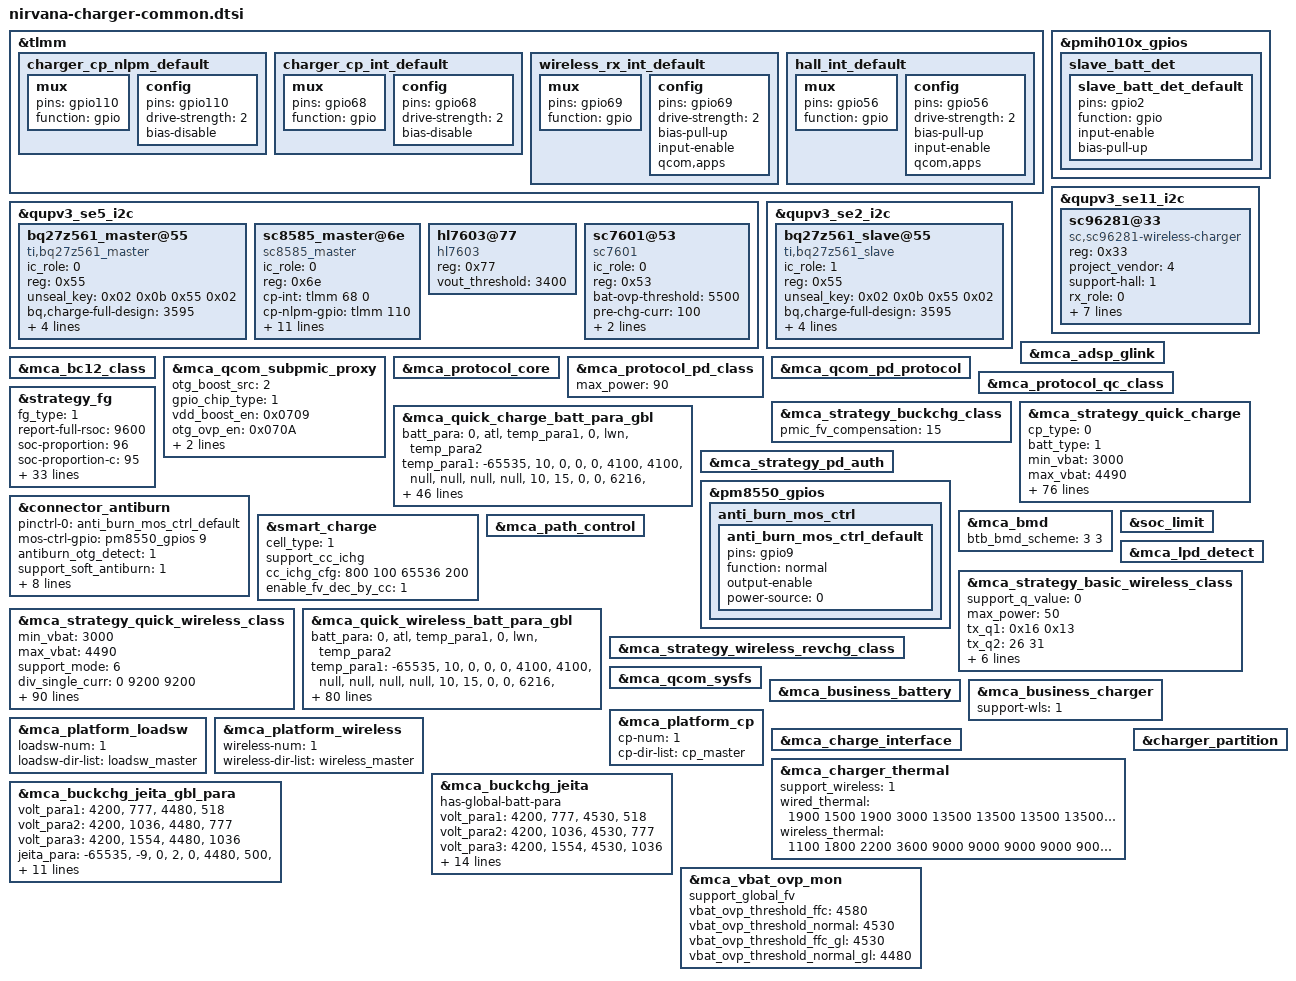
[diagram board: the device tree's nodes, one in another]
#include "mca.dtsi"

&tlmm {
	charger_cp_nlpm_default: charger_cp_nlpm_default {
		mux {
			pins = "gpio110";
			function = "gpio";
		};
		config {
			pins = "gpio110";
			drive-strength = <2>;   /* 2 mA */
			bias-disable;
		};
	};

	charger_cp_int_default: charger_cp_int_default {
		mux {
			pins = "gpio68";
			function = "gpio";
		};
		config {
			pins = "gpio68";
			drive-strength = <2>;   /* 2 mA */
			bias-disable;
		};
	};

	wireless_rx_int_default: wireless_rx_int_default {
		mux {
			pins = "gpio69";
			function = "gpio";
		};

		config {
			pins = "gpio69";
			drive-strength = <2>;
			bias-pull-up;
			input-enable;
			qcom,apps;
		};
	};

	hall_int_default: hall_int_default {
		mux {
			pins = "gpio56";
			function = "gpio";
		};

		config {
			pins = "gpio56";
			drive-strength = <2>;
			bias-pull-up;
			input-enable;
			qcom,apps;
		};
	};
};

&pmih010x_gpios {
	slave_batt_det {
		slave_batt_det_default: slave_batt_det_default {
			pins = "gpio2";
			function = "gpio";
			input-enable;
			bias-pull-up;
		};
	};
};


&qupv3_se5_i2c {
	status = "ok";
	#address-cells = <1>;
	#size-cells = <0>;
	bq27z561_master@55 {
		compatible = "ti,bq27z561_master";
		ic_role = <0>;
		reg = <0x55>;
		unseal_key = <0x02 0x0b 0x55 0x02>;
		bq,charge-full-design = <3595>;
		soh_th = <92>;
		cycle_th = <400>;
		cycle_step = <50>;
		resistance-id = <100000>;
		status = "ok";
	};

	sc8585_master@6e {
		compatible = "sc8585_master";
		status = "ok";
		ic_role = <0>;
		reg = <0x6e>;
		cp-int= <&tlmm 68 0>;
		cp-nlpm-gpio = <&tlmm 110 0x00>;
		pinctrl-names = "default";
		pinctrl-0 = <&charger_cp_nlpm_default>, <&charger_cp_int_default>;
		bat-ovp-threshold = <4700>;
		bat-ovp-alarm-threshold = <4650>;
		bus-ovp-threshold = <21000 11000 6000>;
		usb-ovp-threshold = <21000 14000 7500>;
		bus-ocp-threshold = <5000 5500 5000>;
		wpc-ovp-threshold = <21000>;
		out-ovp-threshold = <5000>;
		pmid2-uvp-threshold = <100>;
		pmid2-ovp-threshold = <600>;

	};

	hl7603@77 {
		compatible = "hl7603";
		reg = <0x77>;
		vout_threshold = <3400>;
	};

	sc7601@53 {
		compatible = "sc7601";
		ic_role = <0>;
		reg = <0x53>;
		bat-ovp-threshold = <5500>;
		pre-chg-curr = <100>;
		vfc-chg-volt = <3100>;
		limit-chg-curr = <7000>;
	};
};

&qupv3_se2_i2c {
	status = "ok";
	#address-cells = <1>;
	#size-cells = <0>;
	bq27z561_slave@55 {
		compatible = "ti,bq27z561_slave";
		ic_role = <1>;
		reg = <0x55>;
		unseal_key = <0x02 0x0b 0x55 0x02>;
		bq,charge-full-design = <3595>;
		soh_th = <92>;
		cycle_th = <400>;
		cycle_step = <50>;
		resistance-id = <100000>;
		status = "ok";
	};
};

&qupv3_se11_i2c {
	status = "ok";
	#address-cells = <1>;
	#size-cells = <0>;
	sc96281@33 {
		compatible = "sc,sc96281-wireless-charger";
		reg = <0x33>;
		project_vendor = <4>;
		support-hall = <1>;
		rx_role = <0>;
		fw_version_index = <2>;
		pinctrl-names = "rx_int_pull_up", "hall_int_pull_up";
		pinctrl-0 = <&wireless_rx_int_default>;
		pinctrl-1 = <&hall_int_default>;
		rx-int = <&tlmm 69 0x00>;
		pwr-det-int = <&tlmm 96 0x00>;
		sleep-rx-gpio = <&tlmm 94 0x00>;
		hall-int2 = <&tlmm 56 0x00>;
	};
};

&mca_adsp_glink {
	status = "ok";
};

&mca_bc12_class {
	status = "ok";
};

&mca_qcom_subpmic_proxy {
	status = "ok";
	otg_boost_src = <2>;
	gpio_chip_type = <1>;
	vdd_boost_en = <0x0709>;
	otg_ovp_en = <0x070A>;
	mi,support-cid = <1>;
	cid_gpio_int = <0x0708>;
};

&mca_protocol_core {
	status = "ok";
};

&mca_protocol_pd_class {
	status = "ok";
	max_power = <90>;
};

&mca_qcom_pd_protocol {
	status = "ok";
};

&mca_protocol_qc_class {
	status = "ok";
};

&mca_strategy_buckchg_class {
	status = "ok";
	pmic_fv_compensation = <15>;
};

&mca_strategy_quick_charge {
	status = "ok";
	cp_type = <0>;
	batt_type = <1>;
	min_vbat = <3000>;
	max_vbat = <4490>;
	div_delta_volt = <300 300 600>;
	div_single_curr = <4500 11000 15600>;
	div_max_curr = <5000 12000 15600>;
	ibus_compensation = <600 300 200>;
	max_power = <67000>;
	qc_normal_charge_fv = <4510>;
	pps_taper_vol_hys = <5>;
	hardware_cv = <1>;
	support_mode = <6>;
	has-global-batt-para;
	support_cp_vfc = <1>;
	support_curr_monitor = <1>;

	vstep_para =
		"1", "800", "2000", "0", "2",
		"2", "800", "2000", "0", "4",
		"4", "800", "8000", "0", "25",
		"4", "800", "4000", "0", "17",
		"4", "800", "2000", "0", "8",
		"4", "800", "1200", "0", "5",
		"4", "800", "800", "0", "2";

	batt_para =
		"0", "coslight", "temp_para1";
	base_flip_para =
		"0", "coslight", "base_batt_para",
		"1", "coslight", "flip_batt_para";

	/*total battery para*/
	/* temp_low, temp_high, low_temp_hys, high_temp_hys, max_current, normal_fv, ffc_fv,volt_para_name stage_para_name*/
	temp_para1 =
		"-65535", "10", "0", "0", "0", "4100", "4100", "null", "null", "null", "null",
		"10", "15", "0", "0", "6768",  "4550", "4550", "normal_para_10_15", "null", "null", "null",
		"15", "20", "0", "0", "8534", "4550", "4550", "normal_para_15_20", "null", "null", "null",
		"20", "48", "2", "2", "13800", "4530", "4570", "normal_para_20_48", "ffc_para_20_48", "null", "ffc_stage_20_48",
		"48", "65535", "0", "0", "0", "4100", "4100", "null", "null", "null", "null";

	normal_para_10_15 =
		"4200", "6768", "5890",
		"4550", "5890", "400";

	normal_para_15_20 =
		"4200", "8534", "5890",
		"4550", "5890", "400";

	normal_para_20_48 =
		"4230", "13800", "5890",
		"4530", "5890", "400";

	ffc_para_20_48 =
		"4230", "13800", "11941",
		"4300", "11941", "10320",
		"4450", "10320", "5890",
		"4570", "5890", "1968";

	ffc_stage_20_48 = <0 0 0 0 0 0 0 0>;

	/*base battery para*/
	/* temp_low, temp_high, low_temp_hys, high_temp_hys, max_current, normal_fv, ffc_fv,volt_para_name stage_para_name*/
	base_batt_para =
		"-65535", "10", "0", "0", "0", "4100", "4100", "null", "null", "null", "null",
		"10", "15", "0", "0", "6768",  "4550", "4550", "base_normal_para_10_15", "null", "null", "null",
		"15", "20", "0", "0", "8534", "4550", "4550", "base_normal_para_15_20", "null", "null", "null",
		"20", "48", "2", "2", "13800", "4530", "4570", "base_normal_para_20_48", "base_ffc_para_20_48", "null", "base_ffc_stage_20_48",
		"48", "65535", "0", "0", "0", "4100", "4100", "null", "null", "null", "null";

	base_normal_para_10_15 =
		"4200", "3096", "2705",
		"4550", "2705", "200";

	base_normal_para_15_20 =
		"4200", "3907", "2705",
		"4550", "2705", "200";

	base_normal_para_20_48 =
		"4230", "7150", "2705",
		"4530", "2705", "200";

	base_ffc_para_20_48 =
		"4230", "7150", "6221",
		"4300", "6221", "5410",
		"4450", "5410", "2705",
		"4570", "2705", "984";

	base_ffc_stage_20_48 = <0 0 0 0 0 0 0 0>;

	/*flip battery para*/
	/* temp_low, temp_high, low_temp_hys, high_temp_hys, max_current, normal_fv, ffc_fv,volt_para_name stage_para_name*/
	flip_batt_para =
		"-65535", "10", "0", "0", "0", "4100", "4100", "null", "null", "null", "null",
		"10", "15", "0", "0", "6768",  "4550", "4550", "flip_normal_para_10_15", "null", "null", "null",
		"15", "20", "0", "0", "8534", "4550", "4550", "flip_normal_para_15_20", "null", "null", "null",
		"20", "48", "2", "2", "13800", "4530", "4570", "flip_normal_para_20_48", "flip_ffc_para_20_48", "null", "flip_ffc_stage_20_48",
		"48", "65535", "0", "0", "0", "4100", "4100", "null", "null", "null", "null";

	flip_normal_para_10_15 =
		"4200", "3672", "3185",
		"4550", "3185", "200";

	flip_normal_para_15_20 =
		"4200", "4627", "3185",
		"4550", "3185", "200";

	flip_normal_para_20_48 =
		"4230", "6650", "3185",
		"4530", "3185", "200";

	flip_ffc_para_20_48 =
		"4230", "6650", "5720",
		"4300", "5720", "4910",
		"4450", "4910", "3185",
		"4570", "3185", "984";

	flip_ffc_stage_20_48 = <0 0 0 0 0 0 0 0>;
};

&mca_quick_charge_batt_para_gbl {
	batt_para =
		"0", "atl", "temp_para1",
		"0", "lwn", "temp_para2";
	/* temp_low, temp_high, low_temp_hys, high_temp_hys, max_current, normal_fv, ffc_fv,volt_para_name stage_para_name*/
	temp_para1 =
		"-65535", "10", "0", "0", "0", "4100", "4100", "null", "null", "null", "null",
		"10", "15", "0", "0", "6216",  "4480", "4480", "normal_volt_para1_1", "null", "null", "null",
		"15", "20", "0", "0", "12250", "4480", "4530", "normal_volt_para1_2", "ffc_volt_para1_2", "null", "ffc_stage_para1_2",
		"20", "48", "2", "2", "15600", "4480", "4530", "normal_volt_para1_3", "ffc_volt_para1_3", "null", "ffc_stage_para1_3",
		"48", "65535", "0", "0", "0", "4100", "4100", "null", "null", "null", "null";

	normal_volt_para1_1 =
		"4200", "6216", "5180",
		"4473", "5180", "800";

	normal_volt_para1_2 =
		"4250", "12250", "6216",
		"4473", "6216", "800";
	ffc_volt_para1_2 =
		"4250", "12250", "9324",
		"4400", "9324", "7770",
		"4480", "7770", "6216",
		"4523", "6216", "870";
	ffc_stage_para1_2 = <0 1 0 0 0 0 0 0>;

	normal_volt_para1_3 =
		"4300", "15600", "6216",
		"4473", "6216", "800";
	ffc_volt_para1_3 =
		"4300", "15600", "12400",
		"4350", "12400", "9324",
		"4400", "9324", "7770",
		"4480", "7770", "6216",
		"4523", "6216", "2000";
	ffc_stage_para1_3 = <0 1 0 0 0 0 0 0 0 0>;

	temp_para2 =
		"-65535", "10", "0", "0", "0", "4100", "4100", "null", "null", "null", "null",
		"10", "15", "0", "0", "6216",  "4480", "4480", "normal_volt_para2_1", "null", "null", "null",
		"15", "20", "0", "0", "12250", "4480", "4530", "normal_volt_para2_2", "ffc_volt_para2_2", "null", "ffc_stage_para2_2",
		"20", "48", "2", "2", "15600", "4480", "4530", "normal_volt_para2_3", "ffc_volt_para2_3", "null", "ffc_stage_para2_3",
		"48", "65535", "0", "0", "0", "4100", "4100", "null", "null", "null", "null";

	normal_volt_para2_1 =
		"4200", "6216", "5180",
		"4473", "5180", "800";

	normal_volt_para2_2 =
		"4250", "12250", "6216",
		"4473", "6216", "800";
	ffc_volt_para2_2 =
		"4250", "12250", "9324",
		"4400", "9324", "7770",
		"4480", "7770", "6216",
		"4523", "6216", "984";
	ffc_stage_para2_2 = <0 1 0 0 0 0 0 0>;

	normal_volt_para2_3 =
		"4270", "15600", "6216",
		"4473", "6216", "800";
	ffc_volt_para2_3 =
		"4270", "15600", "12400",
		"4320", "12400", "9324",
		"4400", "9324", "7770",
		"4480", "7770", "6216",
		"4523", "6216", "2000";
	ffc_stage_para2_3 = <0 1 0 0 0 0 0 0 0 0>;
};

&mca_strategy_pd_auth {
	status = "ok";
};


&strategy_fg {
	status = "ok";
	fg_type = <1>;
	report-full-rsoc = <9600>;
	soc-proportion = <96>;
	soc-proportion-c = <95>;
	vcutoff_shutdown_delay = <3050>;
	vcutoff_sw = <2900>;
	vcutoff_fw = <3050>;
	support-cc-vcutoff;
	support-vpack-low-shutdown;
	cc_vcutoff_cfg =
		"-65535", "65535", "0", "0", "cc_para0";
	cc_para0 =
		"800", "3050", "3050", "2900",
		"1200", "3250", "3250", "2900",
		"65535", "3430", "3430", "2900";
	support-dod-vcutoff;
	/*temp_low, temp_high, low_temp_hys, high_temp_hys, vterm, vterm_para_name*/
	dod_vcutoff_cfg =
		"-65535", "0", "0", "0", "dod_para0",
		"0", "10", "0", "0", "dod_para1",
		"10", "60", "0", "0", "dod_para2",
		"60", "65535", "0", "0", "dod_para3";
	/*dod_count, vterm_fw, vterm_shutdown_delay, vempty*/
	dod_para0 =
		"80", "3050", "2850","2700",
		"120", "3050", "2950","2800",
		"65535", "3050", "3050","2900";
	dod_para1 =
	 	"136", "3050", "3050","2900",
	 	"65535", "3150", "3150","2900";
	dod_para2 =
		"48", "3050", "3050", "2900",
		"136", "3150", "3150", "2900",
		"65535", "3250", "3250", "2900";
	dod_para3 =
		"65535", "3050", "3050","2900";
	adapt_power = <67>;
	model-name = "O3_5400mah_90w";
	model-name-global = "O3_5240mah_90w";
	support_full_design_gl;
	charge-full-design = <5400>;
	charge-full-design-gl = <5240>;
	support_dtpt = <1>;
	support-lossless-rechg = <1>;
	lossless_rechg_cfg = <15 47 300>;
	iterm_para =
		"0", "iterm_para1",
		"1", "iterm_para2";
	/* temp, temp_hys, normal_iterm, ffc_iterm*/
	iterm_para1 =
		"10", "2", "197", "200",
		"15", "2", "187", "743",
		"35", "2", "187", "956",
		"40", "2", "187", "1204";

	iterm_para2 =
		"10", "2", "79", "200",
		"15", "2", "69", "743",
		"35", "2", "69", "956",
		"40", "2", "69", "1204";
};

&pm8550_gpios {
        anti_burn_mos_ctrl {
                anti_burn_mos_ctrl_default: anti_burn_mos_ctrl_default {
                        pins = "gpio9";
                        function = "normal";
                        output-enable;
                        //drive-strength = <2>;
                        power-source = <0>;
                };
        };
};

&connector_antiburn {
	status = "ok";
	pinctrl-names = "default";
	pinctrl-0 = <&anti_burn_mos_ctrl_default>;
	mos-ctrl-gpio = <&pm8550_gpios 9 0>;
	antiburn_otg_detect = <1>;
	support_soft_antiburn = <1>;
	support_hw_antiburn = <1>;
	use_double_ntc = <1>;
	monitor_interval = <1000>;
	thermal-zone-name = "conn_therm";
	thermal-zone-name2 = "conn_therm2";
	max_temp_increase_rate = <4>; /*ntc temperature increase speed per second.*/
	otg_boost_src = <2>;   //BOOST_SRC_EXTERNAL
	en_src = <0>;      //OTG_EN_BOOST
        //thermal-board-temp-name = "board_sensor_therm";
};

&mca_bmd {
	status = "ok";
	btb_bmd_scheme = <3 3>;
};

&smart_charge {
	status = "ok";
	cell_type = <1>;
	support_cc_ichg;
	cc_ichg_cfg = </* cyclecount delta_ichg*/
	800 100
	65536 200>;
	enable_fv_dec_by_cc = <1>;
};

&soc_limit {
	status = "ok";
};

&mca_path_control {
	status = "ok";
};

&mca_lpd_detect {
	status = "ok";
};

&mca_strategy_basic_wireless_class {
	status = "ok";
	support_q_value = <0>;
	max_power = <50>;
	//low_inductance_tx_50w, low_inductance_tx_80w
	tx_q1 = /bits/ 8 <0x16 0x13>;
	tx_q2 = <26 31>;
	rx_max_iout = <2650 2650>;
	ffc_temp_low = <15>;
	ffc_temp_high = <48>;
	support-hall = <1>;
	phone_vol = <7000>;
	offstd_phone_icl = <200>;
};

&mca_strategy_quick_wireless_class {
	status = "ok";
	min_vbat = <3000>;
	max_vbat = <4490>;
	support_mode = <6>;
	div_single_curr = <0 9200 9200>;
	div_max_curr = <0 9200 9200>;
	has-global-batt-para;
	support-hall = <1>;
	batt_para =
		"0", "coslight", "temp_para1",
		"0", "lwn", "temp_para2";
	/* temp_low, temp_high, low_temp_hys, high_temp_hys, max_current, normal_fv, ffc_fv, volt_para_name stage_para_name*/
	temp_para1 =
		"-65535", "10", "0", "0", "0", "4100", "4100", "null", "null", "null", "null",
		"10", "15", "0", "0", "6216", "4530", "4530", "normal_volt_para1_1", "null", "null", "null",
		"15", "20", "0", "0", "12250", "4510", "4580", "normal_volt_para1_2", "ffc_volt_para1_2", "null", "ffc_stage_para1_2",
		"20", "35", "2", "2", "15600", "4510", "4580", "normal_volt_para1_3", "ffc_volt_para1_3", "null", "ffc_stage_para1_3",
		"35", "40", "2", "2", "15600", "4510", "4580", "normal_volt_para1_4", "ffc_volt_para1_4", "null", "ffc_stage_para1_4",
		"40", "48", "2", "2", "15600", "4510", "4580", "normal_volt_para1_5", "ffc_volt_para1_5", "null", "ffc_stage_para1_5",
		"48", "65535", "0", "0", "0", "4100", "4100", "null", "null", "null", "null";

	normal_volt_para1_1 =
		"4200", "6216", "5180",
		"4530", "5180", "800";

	normal_volt_para1_2 =
		"4250", "12250", "6216",
		"4510", "6216", "800";
	ffc_volt_para1_2 =
		"4250", "12250", "9324",
		"4400", "9324", "7770",
		"4500", "7770", "6216",
		"4570", "6216", "2300";
	ffc_stage_para1_2 = <0 1 0 0 0 0 0 0>;

	normal_volt_para1_3 =
		"4320", "15600", "6216",
		"4510", "6216", "800";
	ffc_volt_para1_3 =
		"4320", "15600", "12400",
		"4350", "12400", "9324",
		"4400", "9324", "7770",
		"4500", "7770", "6216",
		"4570", "6216", "2300";
	ffc_stage_para1_3 = <0 1 0 0 0 0 0 0 0 0>;

	normal_volt_para1_4 =
		"4320", "15600", "6216",
		"4510", "6216", "800";
	ffc_volt_para1_4 =
		"4320", "15600", "12400",
		"4350", "12400", "9324",
		"4400", "9324", "7770",
		"4500", "7770", "6216",
		"4570", "6216", "3000";
	ffc_stage_para1_4 = <0 1 0 0 0 0 0 0 0 0>;

	normal_volt_para1_5 =
		"4320", "15600", "6216",
		"4510", "6216", "800";
	ffc_volt_para1_5 =
		"4320", "15600", "12400",
		"4350", "12400", "9324",
		"4400", "9324", "7770",
		"4500", "7770", "6216",
		"4570", "6216", "3000";
	ffc_stage_para1_5 = <0 1 0 0 0 0 0 0 0 0>;

	temp_para2 =
		"-65535", "10", "0", "0", "0", "4100", "4100", "null", "null", "null", "null",
		"10", "15", "0", "0", "6216", "4530", "4530", "normal_volt_para2_1", "null", "null", "null",
		"15", "20", "0", "0", "12250", "4510", "4580", "normal_volt_para2_2", "ffc_volt_para2_2", "null", "ffc_stage_para2_2",
		"20", "35", "2", "2", "15600", "4510", "4580", "normal_volt_para2_3", "ffc_volt_para2_3", "null", "ffc_stage_para2_3",
		"35", "40", "2", "2", "15600", "4510", "4580", "normal_volt_para2_4", "ffc_volt_para2_4", "null", "ffc_stage_para2_4",
		"40", "48", "2", "2", "15600", "4510", "4580", "normal_volt_para2_5", "ffc_volt_para2_5", "null", "ffc_stage_para2_5",
		"48", "65535", "0", "0", "0", "4100", "4100", "null", "null", "null", "null";

	normal_volt_para2_1 =
		"4200", "6216", "5180",
		"4530", "5180", "800";

	normal_volt_para2_2 =
		"4250", "12250", "6216",
		"4510", "6216", "800";
	ffc_volt_para2_2 =
		"4250", "12250", "9324",
		"4400", "9324", "7770",
		"4500", "7770", "6216",
		"4570", "6216", "2300";
	ffc_stage_para2_2 = <0 1 0 0 0 0 0 0>;

	normal_volt_para2_3 =
		"4290", "15600", "6216",
		"4510", "6216", "800";
	ffc_volt_para2_3 =
		"4290", "15600", "12400",
		"4320", "12400", "9324",
		"4400", "9324", "7770",
		"4500", "7770", "6216",
		"4570", "6216", "2300";
	ffc_stage_para2_3 = <0 1 0 0 0 0 0 0 0 0>;

	normal_volt_para2_4 =
		"4290", "15600", "6216",
		"4510", "6216", "800";
	ffc_volt_para2_4 =
		"4290", "15600", "12400",
		"4320", "12400", "9324",
		"4400", "9324", "7770",
		"4500", "7770", "6216",
		"4570", "6216", "3000";
	ffc_stage_para2_4 = <0 1 0 0 0 0 0 0 0 0>;

	normal_volt_para2_5 =
		"4290", "15600", "6216",
		"4510", "6216", "800";
	ffc_volt_para2_5 =
		"4290", "15600", "12400",
		"4320", "12400", "9324",
		"4400", "9324", "7770",
		"4500", "7770", "6216",
		"4570", "6216", "3000";
	ffc_stage_para2_5 = <0 1 0 0 0 0 0 0 0 0>;

	vstep_para =
		"1", "2000", "2",
		"2", "2000", "4",
		"4", "4000", "25",
		"4", "3000", "25",
		"4", "2000", "6",
		"4", "1000", "3",
		"4", "500", "2",
		"4", "200", "1";
};

&mca_quick_wireless_batt_para_gbl {
	batt_para =
		"0", "atl", "temp_para1",
		"0", "lwn", "temp_para2";
	/* temp_low, temp_high, low_temp_hys, high_temp_hys, max_current, normal_fv, ffc_fv, volt_para_name stage_para_name*/
	temp_para1 =
		"-65535", "10", "0", "0", "0", "4100", "4100", "null", "null", "null", "null",
		"10", "15", "0", "0", "6216", "4480", "4480", "normal_volt_para1_1", "null", "null", "null",
		"15", "20", "0", "0", "12250", "4480", "4530", "normal_volt_para1_2", "ffc_volt_para1_2", "null", "ffc_stage_para1_2",
		"20", "35", "2", "2", "15600", "4480", "4530", "normal_volt_para1_3", "ffc_volt_para1_3", "null", "ffc_stage_para1_3",
		"35", "40", "2", "2", "15600", "4480", "4530", "normal_volt_para1_4", "ffc_volt_para1_4", "null", "ffc_stage_para1_4",
		"40", "48", "2", "2", "15600", "4480", "4530", "normal_volt_para1_5", "ffc_volt_para1_5", "null", "ffc_stage_para1_5",
		"48", "65535", "0", "0", "0", "4100", "4100", "null", "null", "null", "null";

	normal_volt_para1_1 =
		"4200", "6216", "5180",
		"4480", "5180", "800";

	normal_volt_para1_2 =
		"4250", "12250", "6216",
		"4470", "6216", "800";
	ffc_volt_para1_2 =
		"4250", "12250", "9324",
		"4400", "9324", "7770",
		"4480", "7770", "6216",
		"4520", "6216", "2300";
	ffc_stage_para1_2 = <0 1 0 0 0 0 0 0>;

	normal_volt_para1_3 =
		"4300", "15600", "6216",
		"4480", "6216", "800";
	ffc_volt_para1_3 =
		"4300", "15600", "12400",
		"4350", "12400", "9324",
		"4400", "9324", "7770",
		"4480", "7770", "6216",
		"4520", "6216", "2300";
	ffc_stage_para1_3 = <0 1 0 0 0 0 0 0 0 0>;

	normal_volt_para1_4 =
		"4300", "15600", "6216",
		"4480", "6216", "800";
	ffc_volt_para1_4 =
		"4300", "15600", "12400",
		"4350", "12400", "9324",
		"4400", "9324", "7770",
		"4480", "7770", "6216",
		"4520", "6216", "3000";
	ffc_stage_para1_4 = <0 1 0 0 0 0 0 0 0 0>;

	normal_volt_para1_5 =
		"4300", "15600", "6216",
		"4480", "6216", "800";
	ffc_volt_para1_5 =
		"4300", "15600", "12400",
		"4350", "12400", "9324",
		"4400", "9324", "7770",
		"4480", "7770", "6216",
		"4520", "6216", "3000";
	ffc_stage_para1_5 = <0 1 0 0 0 0 0 0 0 0>;

	temp_para2 =
		"-65535", "10", "0", "0", "0", "4100", "4100", "null", "null", "null", "null",
		"10", "15", "0", "0", "6216", "4480", "4480", "normal_volt_para2_1", "null", "null", "null",
		"15", "20", "0", "0", "12250", "4480", "4530", "normal_volt_para2_2", "ffc_volt_para2_2", "null", "ffc_stage_para2_2",
		"20", "35", "2", "2", "15600", "4480", "4530", "normal_volt_para2_3", "ffc_volt_para2_3", "null", "ffc_stage_para2_3",
		"35", "40", "2", "2", "15600", "4480", "4530", "normal_volt_para2_4", "ffc_volt_para2_4", "null", "ffc_stage_para2_4",
		"40", "48", "2", "2", "15600", "4480", "4530", "normal_volt_para2_5", "ffc_volt_para2_5", "null", "ffc_stage_para2_5",
		"48", "65535", "0", "0", "0", "4100", "4100", "null", "null", "null", "null";

	normal_volt_para2_1 =
		"4200", "6216", "5180",
		"4480", "5180", "800";

	normal_volt_para2_2 =
		"4250", "12250", "6216",
		"4480", "6216", "800";
	ffc_volt_para2_2 =
		"4250", "12250", "9324",
		"4400", "9324", "7770",
		"4480", "7770", "6216",
		"4520", "6216", "2300";
	ffc_stage_para2_2 = <0 1 0 0 0 0 0 0>;

	normal_volt_para2_3 =
		"4270", "15600", "6216",
		"4480", "6216", "800";
	ffc_volt_para2_3 =
		"4270", "15600", "12400",
		"4320", "12400", "9324",
		"4400", "9324", "7770",
		"4480", "7770", "6216",
		"4520", "6216", "2300";
	ffc_stage_para2_3 = <0 1 0 0 0 0 0 0 0 0>;

	normal_volt_para2_4 =
		"4270", "15600", "6216",
		"4480", "6216", "800";
	ffc_volt_para2_4 =
		"4270", "15600", "12400",
		"4320", "12400", "9324",
		"4400", "9324", "7770",
		"4480", "7770", "6216",
		"4520", "6216", "3000";
	ffc_stage_para2_4 = <0 1 0 0 0 0 0 0 0 0>;

	normal_volt_para2_5 =
		"4270", "15600", "6216",
		"4480", "6216", "800";
	ffc_volt_para2_5 =
		"4270", "15600", "12400",
		"4320", "12400", "9324",
		"4400", "9324", "7770",
		"4480", "7770", "6216",
		"4520", "6216", "3000";
	ffc_stage_para2_5 = <0 1 0 0 0 0 0 0 0 0>;
};

&mca_strategy_wireless_revchg_class {
	status = "ok";
};

&mca_qcom_sysfs {
	status = "ok";
};

&mca_business_battery {
	status = "ok";
};

&mca_business_charger {
	support-wls = <1>;
	status = "ok";
};

&mca_platform_cp {
	status = "ok";
	cp-num = <1>;
	cp-dir-list = "cp_master";
};

&mca_platform_loadsw {
	status = "ok";
	loadsw-num = <1>;
	loadsw-dir-list = "loadsw_master";
};

&mca_platform_wireless {
	status = "ok";
	wireless-num = <1>;
	wireless-dir-list = "wireless_master";
};

&mca_charge_interface
{
	status = "ok";
};

&mca_charger_thermal
{
	status = "ok";
	support_wireless = <1>;
	/* 5v_in 9v_in 5v_ichg 9v_ichg div1_single div1_multi div2_single div2_multi div4_single div4_multi*/
	wired_thermal = <
		1900 1500 1900 3000 13500 13500 13500 13500 13500 13500 /* level 1 */
		1900 1500 1900 3000 11000 11000 11000 11000 11000 11000 /* level 2 */
		1900 1500 1900 3000 9000  9000  9000  9000  9000  9000  /* level 3 */
		1900 1450 1900 3000 8000  8000  8000  8000  8000  8000  /* level 4 */
		1900 1400 1900 3000 7000  7000  7000  7000  7000  7000  /* level 5 */
		1900 1350 1900 2800 6000  6000  6000  6000  6000  6000  /* level 6 */
		1900 1300 1900 2600 5000  5000  5000  5000  5000  5000  /* level 7 */
		1900 1150 1900 2310 4000  4000  4000  4000  4000  4000  /* level 8 */
		1700 1100 1700 2200 3500  3500  3500  3500  3500  3500  /* level 9 */
		1600 1000 1600 2000 3000  3000  3000  3000  3000  3000  /* level 10 */
		1400 900  1500 2000 2500  2500  2500  2500  2500  2500  /* level 11 */
		1200 850  1500 2000 2000  2000  2000  2000  2000  2000  /* level 12 */
		1100 750  1500 1500 1500  1500  1500  1500  1500  1500  /* level 13 */
		1100 650  1000 1000 1000  1000  1000  1000  1000  1000  /* level 14 */
		1100 500  500  500  500   500   500   500   500   500   /* level 15 */
	>;
	/* bpp_in default_epp_in bpp_ichg default_epp_ichg div1_single div1_multi div2_single div2_multi div4_single
		div4_multi*/
	wireless_thermal = <
	1100 1800 2200 3600 9000 9000 9000 9000 9000 9000 /* level 1 */
	1100 1500 2200 3000 8000 8000 8000 8000 8000 8000 /* level 2 */
	1100 1300 2200 2600 7000 7000 7000 7000 7000 7000 /* level 3 */
	1100 1300 2200 2600 6000 6000 6000 6000 6000 6000 /* level 4 */
	700  1300 1400 2600 5000 5000 5000 5000 5000 5000 /* level 5 */
	700  1300 1400 2600 4000 4000 4000 4000 4000 4000 /* level 6 */
	600  800  1200 1600 3500 3500 3500 3500 3500 3500 /* level 7 */
	600  800  1200 1600 3000 3000 3000 3000 3000 3000 /* level 8 */
	500  600  1000 1200 2500 2500 2500 2500 2500 2500 /* level 9 */
	500  600  1000 1200 2000 2000 2000 2000 2000 2000 /* level 10 */
	500  500  1000 1000 1500 1500 1500 1500 1500 1500 /* level 11 */
	500  500  1000 1000 1000 1000 1000 1000 1000 1000 /* level 12 */
	500  500  1000 1000 800  800  800  800  800  800  /* level 13 */
	400  400  800  800  500  500  500  500  500  500  /* level 14 */
	300  300  600  600  300  300  300  300  300  300  /* level 15 */
	>;
};

&mca_buckchg_jeita
{
	status = "ok";
	has-global-batt-para;
	volt_para1 =
		"4200", "777",
		"4530", "518";
	volt_para2 =
		"4200", "1036",
		"4530", "777";
	volt_para3 =
		"4200", "1554",
		"4530", "1036";
	/* temp_low, temp_high, low_temp_hys, high_temp_hys, max_current, vterm, iterm volt_para_name */
	jeita_para =
		"-65535", "-9", "0", "2", "0", "4530", "500", "null",
		"-9", "0", "1", "2", "777", "4530", "259", "volt_para1",
		"0", "5", "1", "2", "1036", "4530", "259", "volt_para2",
		"5", "10", "1", "2", "1554", "4530", "259", "volt_para3",
		"10", "15", "2", "2", "4000", "4530", "259", "null",
		"15", "48", "2", "2", "4000", "4510", "259", "null",
		"48", "55", "2", "2", "2590", "4060", "259", "null",
		"55", "65535", "2", "2", "0", "4060", "230", "null";
	jeita_para_ffc =
		"15", "20", "2", "2", "4000", "4570", "984", "null",
		"20", "35", "2", "2", "4000", "4570", "984", "null",
		"35", "40", "2", "2", "4000", "4570", "984", "null",
		"40", "48", "2", "2", "4000", "4570", "984", "null",
		"48", "55", "2", "2", "2590", "4060", "259", "null",
		"55", "65535", "2", "2", "0", "4060", "230", "null";
};

&mca_buckchg_jeita_gbl_para {
	volt_para1 =
		"4200", "777",
		"4480", "518";
	volt_para2 =
		"4200", "1036",
		"4480", "777";
	volt_para3 =
		"4200", "1554",
		"4480", "1036";
	/* temp_low, temp_high, low_temp_hys, high_temp_hys, max_current, vterm, iterm volt_para_name */
	jeita_para =
		"-65535", "-9", "0", "2", "0", "4480", "500", "null",
		"-9", "0", "1", "2", "777", "4480", "259", "volt_para1",
		"0", "5", "1", "2", "1036", "4480", "259", "volt_para2",
		"5", "10", "1", "2", "1554", "4480", "259", "volt_para3",
		"10", "15", "2", "2", "4000", "4480", "259", "null",
		"15", "48", "2", "2", "4000", "4480", "259", "null",
		"48", "55", "2", "2", "2590", "4060", "259", "null",
		"55", "65535", "2", "2", "0", "4060", "230", "null";
	jeita_para_ffc =
		"15", "20", "2", "2", "4000", "4530", "984", "null",
		"20", "35", "2", "2", "4000", "4530", "1036", "null",
		"35", "40", "2", "2", "4000", "4530", "1295", "null",
		"40", "48", "2", "2", "4000", "4530", "1606", "null";
};

&charger_partition {
	status = "ok";
};

&mca_vbat_ovp_mon {
	support_global_fv;
	vbat_ovp_threshold_ffc = <4580>;
	vbat_ovp_threshold_normal = <4530>;
	vbat_ovp_threshold_ffc_gl = <4530>;
	vbat_ovp_threshold_normal_gl = <4480>;
	status = "ok";
};
